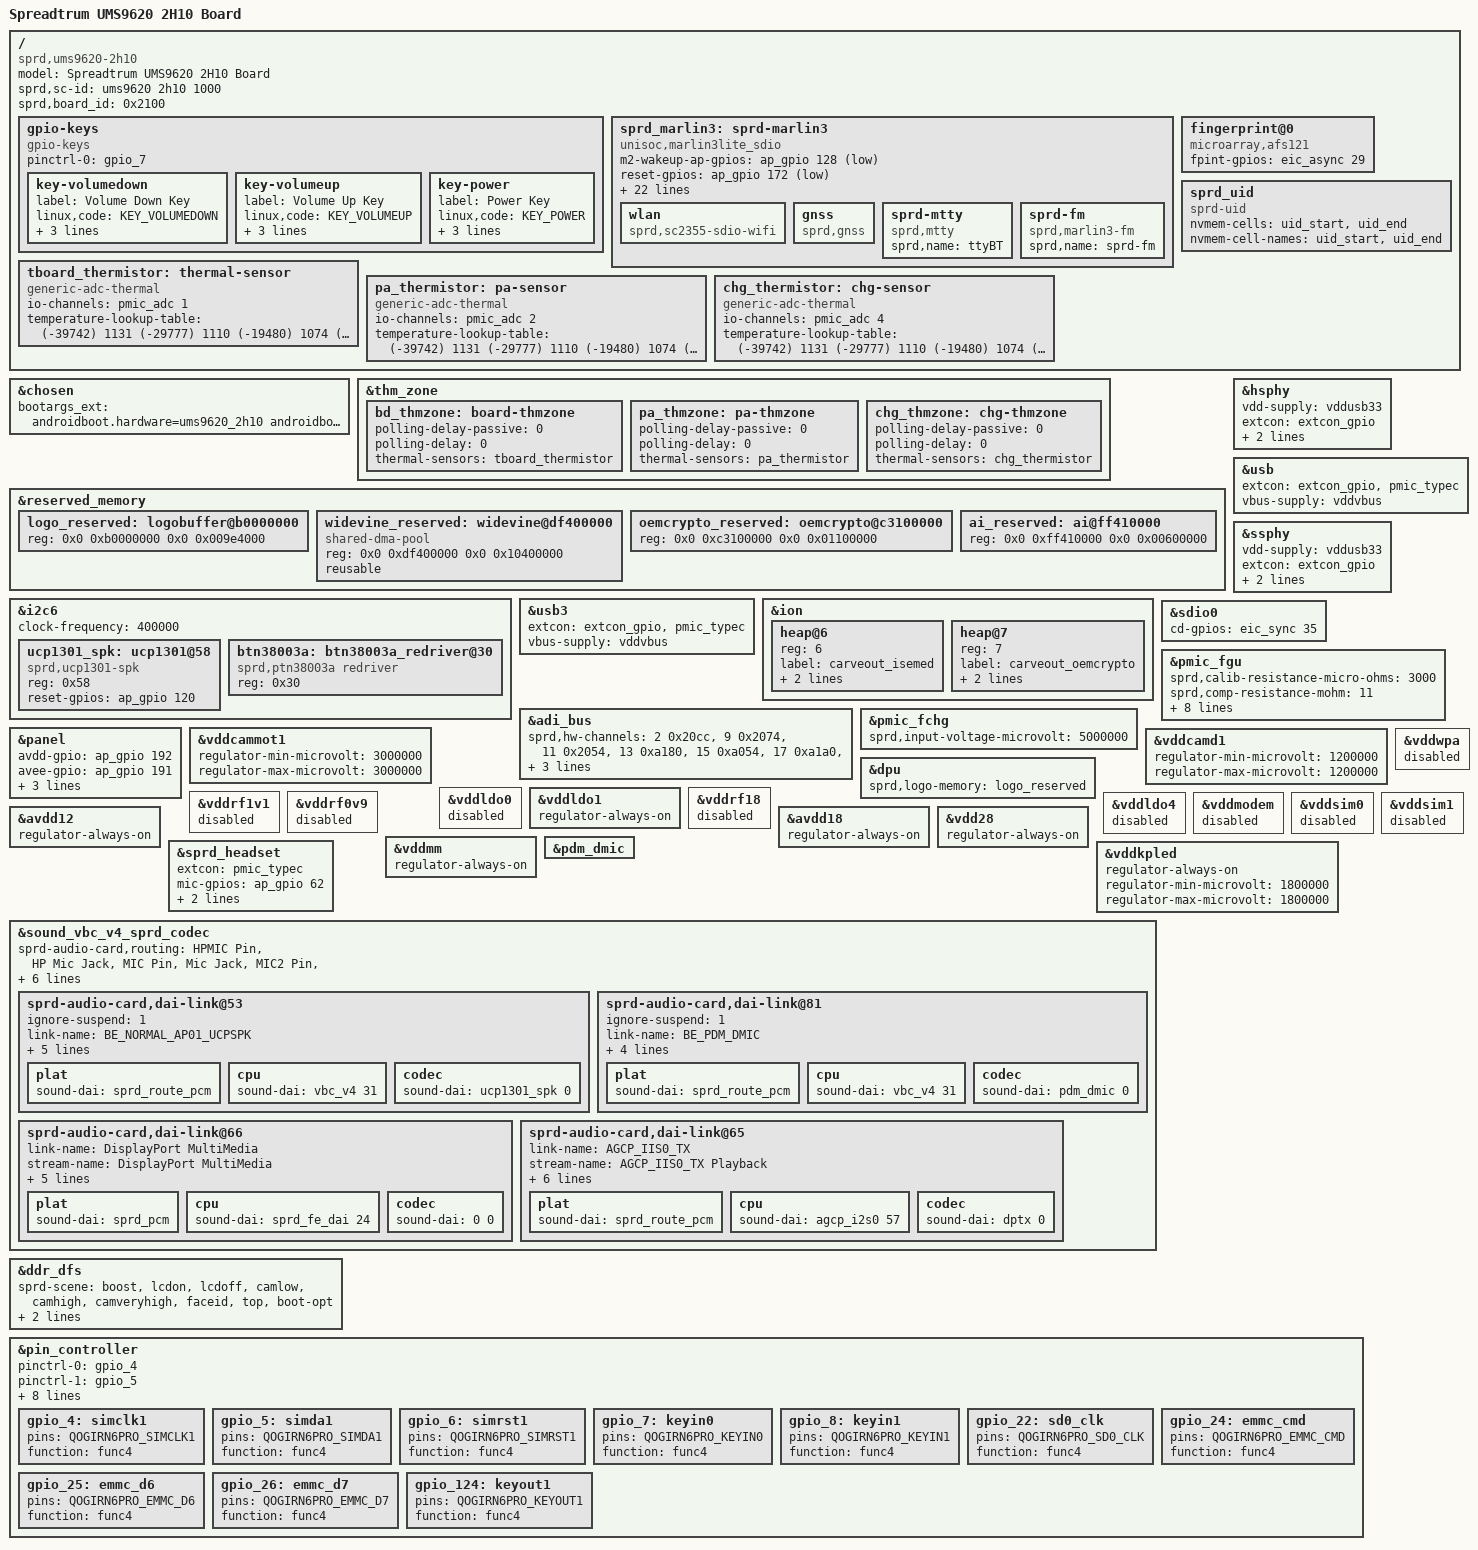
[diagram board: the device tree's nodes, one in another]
/dts-v1/;
/plugin/;
#include <dt-bindings/input/input.h>
#include <dt-bindings/gpio/gpio.h>
#include <dt-bindings/interrupt-controller/arm-gic.h>
#include <dt-bindings/clock/sprd,ums9620-clk.h>
#include <dt-bindings/usb/pd.h>
#include "zte_lcd_visionox_rm692e5_visionox_6p67_fhd_cmd.dtsi"
#include "../lcd/lcd_dummy_mipi.dtsi"
#include "zte_lcd.dtsi"
#include <dt-bindings/mfd/sprd,ump9620-regs.h>
#include <dt-bindings/mfd/sprd,ump9620-mask.h>
#include "zte_nfc_tulip.dtsi"
/ {

	model = "Spreadtrum UMS9620 2H10 Board";

	compatible = "sprd,ums9620-2h10";

	sprd,sc-id = "ums9620 2h10 1000";

	sprd,board_id = <0x2100>; //XX00:base board,XX00~XXFF:customize board

	fragment {
		target-path = "/";
		__overlay__ {

			gpio-keys {
				compatible = "gpio-keys";
				pinctrl-names = "gpio_7";
				pinctrl-0 = <&gpio_7>;

				key-volumedown {
					label = "Volume Down Key";
					linux,code = <KEY_VOLUMEDOWN>;
					gpios = <&ap_gpio 7 GPIO_ACTIVE_LOW>;
					debounce-interval = <2>;
					wakeup-source;
				};

				key-volumeup {
					label = "Volume Up Key";
					linux,code = <KEY_VOLUMEUP>;
					gpios = <&pmic_eic 4 GPIO_ACTIVE_HIGH>;
					debounce-interval = <2>;
					wakeup-source;
				};

				key-power {
					label = "Power Key";
					linux,code = <KEY_POWER>;
					gpios = <&pmic_eic 1 GPIO_ACTIVE_LOW>;
					debounce-interval = <2>;
					wakeup-source;
				};
			};

			sprd_marlin3: sprd-marlin3 {
				compatible = "unisoc,marlin3lite_sdio";
				m2-wakeup-ap-gpios = <&ap_gpio 128 GPIO_ACTIVE_LOW>;
				reset-gpios = <&ap_gpio 172 GPIO_ACTIVE_LOW>;
				enable-gpios = <&ap_gpio 171 GPIO_ACTIVE_LOW>;
				m2-to-ap-irq-gpios = <&ap_gpio 173 GPIO_ACTIVE_LOW>;
				xtal-26m-clk-type = "TCXO";
				avdd12-supply = <&vddwcn>;
				avdd33-supply = <&vddwifipa>;
				dcxo18-supply = <&vddsim2>;

				clock-names = "clk_32k","source","enable";
				clocks = <&aonapb_gate CLK_AUX0>,
					 <&ext_32k>,
					 <&aonapb_gate CLK_AUX0_EB>;
				extcon = <&sdio1>;
				sdhci-name = <&sdio1>;
				sprd,btwf-file-name = "/dev/block/by-name/wcnmodem";
				sprd,gnss-file-name = "/vendor/firmware/gnssmodem.bin";
				adma-tx;
				adma-rx;
				/*
				 * bound parameter:
				 * [0]:addr offset, [1]:mask, [2]:unboundval, [3]:boundval
				 */
				avdd12-parent-bound-chip = <REG_ANA_SLP_DCDC_PD_CTRL MASK_ANA_SLP_DCDCGEN1_PD_EN 0x0 MASK_ANA_SLP_DCDCGEN1_PD_EN>;
				avdd12-bound-wbreq = <REG_ANA_LDO_XTL_EN10 MASK_ANA_LDO_VDDWCN_EXT_XTL3_EN 0x0 MASK_ANA_LDO_VDDWCN_EXT_XTL3_EN>;
				avdd33-bound-wbreq = <REG_ANA_LDO_XTL_EN11 MASK_ANA_LDO_VDDWIFIPA_EXT_XTL3_EN 0x0 MASK_ANA_LDO_VDDWIFIPA_EXT_XTL3_EN>;

				wlan {
					compatible = "sprd,sc2355-sdio-wifi";
				};

				gnss {
					compatible = "sprd,gnss";
				};

				sprd-mtty {
					compatible = "sprd,mtty";
					sprd,name = "ttyBT";
				};

				sprd-fm {
					compatible = "sprd,marlin3-fm";
					sprd,name = "sprd-fm";
				};

			};


			fingerprint@0 {
				compatible = "microarray,afs121";
				fpint-gpios = <&eic_async 29 0>;
			};

			tboard_thermistor: thermal-sensor {
				compatible = "generic-adc-thermal";
				#thermal-sensor-cells = <0>;
				io-channels = <&pmic_adc 1>;
				io-channel-names = "sensor-channel";
				temperature-lookup-table = <
					(-39742) 1131
					(-29777) 1110
					(-19480) 1074
					(-4679) 983
					10110 838
					24805 654
					44922 413
					54903 316
					64895 238
					74884 178
					84883 133
					94883 100
					104880 75
					114889 57
					124872 43 >;
			};

			pa_thermistor: pa-sensor {
				compatible = "generic-adc-thermal";
				#thermal-sensor-cells = <0>;
				io-channels = <&pmic_adc 2>;
				io-channel-names = "sensor-channel";
				temperature-lookup-table = <
					(-39742) 1131
					(-29777) 1110
					(-19480) 1074
					(-4679) 983
					10110 838
					24805 654
					44922 413
					54903 316
					64895 238
					74884 178
					84883 133
					94883 100
					104880 75
					114889 57
					124872 43 >;
			};

			chg_thermistor: chg-sensor {
				compatible = "generic-adc-thermal";
				#thermal-sensor-cells = <0>;
				io-channels = <&pmic_adc 4>;
				io-channel-names = "sensor-channel";
				temperature-lookup-table = <
					(-39742) 1131
					(-29777) 1110
					(-19480) 1074
					(-4679) 983
					10110 838
					24805 654
					44922 413
					54903 316
					64895 238
					74884 178
					84883 133
					94883 100
					104880 75
					114889 57
					124872 43 >;
			};

			sprd_uid {
				compatible = "sprd-uid";
				nvmem-cells = <&uid_start>, <&uid_end>;
				nvmem-cell-names = "uid_start", "uid_end";
			};

		};
	};
};

&chosen {
	bootargs_ext = "androidboot.hardware=ums9620_2h10 androidboot.dtbo_idx=0";
};

&thm_zone {
	bd_thmzone: board-thmzone {
		polling-delay-passive = <0>;
		polling-delay = <0>;
		thermal-sensors = <&tboard_thermistor>;
	};

	pa_thmzone: pa-thmzone {
		polling-delay-passive = <0>;
		polling-delay = <0>;
		thermal-sensors = <&pa_thermistor>;
	};

	chg_thmzone: chg-thmzone {
		polling-delay-passive = <0>;
		polling-delay = <0>;
		thermal-sensors = <&chg_thermistor>;
	};
};

&reserved_memory {
	#address-cells = <2>;
	#size-cells = <2>;
	logo_reserved: logobuffer@b0000000 {
		reg = <0x0 0xb0000000 0x0 0x009e4000>;
	};

	/*Set 8M after widevine to prevent memory out of bounds*/
	widevine_reserved: widevine@df400000 {
		compatible = "shared-dma-pool";
		reg = <0x0 0xdf400000 0x0 0x10400000>;
		reusable;
	};

	/* Encrypt and decrypt widevine video */
	oemcrypto_reserved: oemcrypto@c3100000 {
		reg = <0x0 0xc3100000 0x0 0x01100000>;
	};

	ai_reserved: ai@ff410000 {
		reg = <0x0 0xff410000 0x0 0x00600000>;
	};

};

&i2c6 {
	status = "okay";
	clock-frequency = <400000>;
	#address-cells = <1>;
	#size-cells = <0>;

	ucp1301_spk: ucp1301@58 {
		compatible = "sprd,ucp1301-spk";
		reg = <0x58>;
		reset-gpios = <&ap_gpio 120 GPIO_ACTIVE_HIGH>;
		#sound-dai-cells = <1>;
	};
	btn38003a: btn38003a_redriver@30 {
		compatible = "sprd,ptn38003a redriver";
		reg = <0x30>;
	};

};

&hsphy {
	vdd-supply = <&vddusb33>;
	extcon = <&extcon_gpio>;
	sprd,hsphy-device-eye-pattern = <0x067bd1c0>;
	sprd,hsphy-host-eye-pattern = <0x067bd1c0>;
	status = "okay";
};

&usb {
	extcon = <&extcon_gpio>, <&pmic_typec>;
	vbus-supply = <&vddvbus>;
	status = "okay";
};

&ssphy {
	vdd-supply = <&vddusb33>;
	extcon = <&extcon_gpio>;
	sprd,hsphy-device-eye-pattern = <0x067bd1c0>;
	sprd,hsphy-host-eye-pattern = <0x067bd1c0>;
	status = "okay";
};

&usb3 {
	extcon = <&extcon_gpio>, <&pmic_typec>;
	vbus-supply = <&vddvbus>;
	status = "okay";
};

&ion {
	#address-cells = <1>;
	#size-cells = <0>;

	heap@6 {
		reg = <6>;
		label = "carveout_isemed";
		type = <2>;
		memory-region = <&ise_med_reserved>;
	};

	heap@7 {
		reg = <7>;
		label = "carveout_oemcrypto";
		type = <2>;
		memory-region = <&oemcrypto_reserved>;
	};
};

&adi_bus {
	sprd,hw-channels = <2 0x20cc>, <9 0x2074>, <11 0x2054>, <13 0xa180>,
			<15 0xa054>, <17 0xa1a0>, <19 0xa044>, <21 0xa0e8>,
			<23 0x244c>, <25 0xa074>, <27 0x2044>, <30 0x2020>,
			<32 0x217c>, <33 0x2188>, <34 0x21b8>, <35 0x21ac>;
};

&sdio0 {
	cd-gpios = <&eic_sync 35 GPIO_ACTIVE_HIGH>;
};

&pmic_fgu {
	sprd,calib-resistance-micro-ohms = <3000>;
	sprd,comp-resistance-mohm= <11>;

	fgu-capacity-track;
	phys = <&ssphy>;

	sprd,relax-counter-threshold = <580>;
	sprd,relax-current-threshold = <30>;
	sprd,capacity-sleep-calibration;

	sprd,capacity-boot-calibration;
	sprd,capacity-charge-cycle;
	sprd,basp;
};

&pmic_fchg {
	status = "okay";
	sprd,input-voltage-microvolt = <5000000>;
};

&panel {
	avdd-gpio = <&ap_gpio 192 GPIO_ACTIVE_HIGH>;
	avee-gpio = <&ap_gpio 191 GPIO_ACTIVE_HIGH>;
	reset-gpio = <&ap_gpio 11 GPIO_ACTIVE_HIGH>;
	iovdd-supply = <&vddcamd1>;
	power-supply = <&vddcammot1>;
};

/* enable lcd vddcammot1 */
&vddcammot1 {
	regulator-min-microvolt = <3000000>;
	regulator-max-microvolt = <3000000>;
};

&vddcamd1 {
	regulator-min-microvolt = <1200000>;
	regulator-max-microvolt = <1200000>;
};

&dpu {
	sprd,logo-memory = <&logo_reserved>;

	/* if we need use fastcall for widevine, open the following config */
	// sprd,widevine-use-fastcall;
};

&vddwpa {
	status = "disabled";
};

&vddldo0 {
	status = "disabled";
};

&vddldo1 {
	regulator-always-on;
};

&vddrf18 {
	status = "disabled";
};

&vddrf1v1 {
	status = "disabled";
};

&vddrf0v9 {
	status = "disabled";
};

&vddldo4 {
	status = "disabled";
};

&vddmodem {
	status = "disabled";
};

&vddsim0 {
	status = "disabled";
};

&vddsim1 {
	status = "disabled";
};

&avdd12 {
	regulator-always-on;
};

&avdd18 {
	regulator-always-on;
};

&vdd28 {
	regulator-always-on;
};

&vddmm {
	regulator-always-on;
};

/* enable als/prx sensor vdd */
&vddkpled {
	regulator-always-on;
	regulator-min-microvolt = <1800000>;
	regulator-max-microvolt = <1800000>;
};

&pdm_dmic {
	status = "okay";
};

&sprd_headset {
	status = "okay";
	extcon = <&pmic_typec>;
	mic-gpios = <&ap_gpio 62 GPIO_ACTIVE_HIGH>;
	lr-gpios = <&ap_gpio 61 GPIO_ACTIVE_HIGH>;
	sprd,3pole-adc-threshold = <112>;
};

&sound_vbc_v4_sprd_codec {
	status = "okay";
	sprd-audio-card,routing =
		"HPMIC Pin", "HP Mic Jack",
		"MIC Pin", "Mic Jack",
		"MIC2 Pin", "Aux Mic Jack",
		"MIC3 Pin", "Aux Mic2 Jack",
		"HeadPhone Jack", "HP Pin",
		"Ext Spk", "SPK Pin",
		"UCP1301 SPK ON", "SPK Pin",
		"Ext Spk", "UCP1301 SPK",
		"PDM DMIC2 ON", "SPK Pin",
		"Ext Spk", "PDM_DMIC2",
		"DMIC Pin", "DMic Jack",
		"DMIC1 Pin", "DMic1 Jack",
		"Ext Ear", "EAR Pin";

	/* 35: ucp1301 normal ap01 */
	sprd-audio-card,dai-link@53 {
		ignore-suspend = <1>;
		link-name = "BE_NORMAL_AP01_UCPSPK";
		stream-name = "BE_ST_NORMAL_AP01_UCPSPK";
		no-pcm = <1>;
		dpcm-playback = <1>;
		be-id = <0>;
		dai-format = "i2s";
		plat {
			sound-dai = <&sprd_route_pcm>;
		};
		cpu {
			sound-dai = <&vbc_v4 31>;
		};
		codec {
			sound-dai = <&ucp1301_spk 0>;
		};
	};

	/*
	 * node 54 and node 55 (index 36 and 37) are reserved for
	 * "ucp1301-spk2" and "ucp1301-rcv"
	 * nodes from 56 to 67 (index from 38 to 49) are used by HIFI
	 */
	/* 63: pdm dmic */
	sprd-audio-card,dai-link@81 {
		ignore-suspend = <1>;
		link-name = "BE_PDM_DMIC";
		stream-name = "BE_ST_PDM_DMIC";
		no-pcm = <1>;
		dpcm-capture = <1>;
		be-id = <0>;
		//dai-format = "i2s";
		plat {
			sound-dai = <&sprd_route_pcm>;
		};
		cpu {
			sound-dai = <&vbc_v4 31>;
		};
		codec {
			sound-dai = <&pdm_dmic 0>;
		};
	};

	/* 24: fe DisplayPort pcm */
	sprd-audio-card,dai-link@66 {
		link-name = "DisplayPort MultiMedia";
		stream-name = "DisplayPort MultiMedia";
		be-id = <0>;
		trigger = <1 1>;
		ignore-suspend = <1>;
		dynamic = <1>;
		dpcm-playback = <1>;
		plat {
			sound-dai = <&sprd_pcm>;
		};
		cpu {
			sound-dai = <&sprd_fe_dai 24>;
		};
		codec {
			sound-dai = <0 0>;
		};
	};

	/* agcp_i2s0: be dp pcm */
	sprd-audio-card,dai-link@65 {
		link-name = "AGCP_IIS0_TX";
		stream-name = "AGCP_IIS0_TX Playback";
		be-id = <0>;
		dai-format = "i2s";
		ignore-suspend = <1>;
		no-pcm = <1>;
		dpcm-playback = <1>;
		ignore-pmdown-time = <1>;
		plat {
			sound-dai = <&sprd_route_pcm>;
		};
		cpu {
			sound-dai = <&agcp_i2s0 57>;
		};
		codec {
			sound-dai = <&dptx 0>;
		};
	};
};

&ddr_dfs {
	  sprd-scene = "boost", "lcdon", "lcdoff", "camlow",
			"camhigh", "camveryhigh", "faceid", "top", "boot-opt";
	  sprd-freq = <1244 768 384 1536 1536 1866 1244 1866 1866>;
};

&pin_controller {
	pinctrl-names =
	/* IM1_CLK ,SIM1_DA ,SIM1_RST ,keyin0 */
	 "gpio_4", "gpio_5", "gpio_6", "gpio_7",
	/* keyin1 ,sd0_clk, emmc_cmd */
	"gpio_8", "gpio_22", "gpio_24",
	/* emmc_d6, emmc_d7, emmc_d7 */
	"gpio_25", "gpio_26", "gpio_124";

	pinctrl-0 = <&gpio_4>;
	pinctrl-1 = <&gpio_5>;
	pinctrl-2 = <&gpio_6>;
	pinctrl-3 = <&gpio_7>;
	pinctrl-4 = <&gpio_8>;
	pinctrl-5 = <&gpio_22>;
	pinctrl-6 = <&gpio_24>;
	pinctrl-7 = <&gpio_25>;
	pinctrl-8 = <&gpio_26>;
	pinctrl-9 = <&gpio_124>;

	gpio_4: simclk1 {
		pins = "QOGIRN6PRO_SIMCLK1";
		function = "func4";
	};

	gpio_5: simda1 {
		pins = "QOGIRN6PRO_SIMDA1";
		function = "func4";
	};

	gpio_6: simrst1 {
		pins = "QOGIRN6PRO_SIMRST1";
		function = "func4";
	};

	gpio_7: keyin0 {
		pins = "QOGIRN6PRO_KEYIN0";
		function = "func4";
	};

	gpio_8: keyin1 {
		pins = "QOGIRN6PRO_KEYIN1";
		function = "func4";
	};

	gpio_22: sd0_clk {
		pins = "QOGIRN6PRO_SD0_CLK";
		function = "func4";
	};

	gpio_24: emmc_cmd {
		pins = "QOGIRN6PRO_EMMC_CMD";
		function = "func4";
	};

	gpio_25: emmc_d6 {
		pins = "QOGIRN6PRO_EMMC_D6";
		function = "func4";
	};

	gpio_26: emmc_d7 {
		pins = "QOGIRN6PRO_EMMC_D7";
		function = "func4";
	};

	gpio_124: keyout1 {
		pins = "QOGIRN6PRO_KEYOUT1";
		function = "func4";
	};
};
